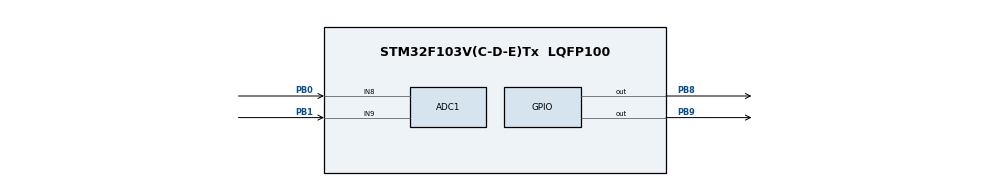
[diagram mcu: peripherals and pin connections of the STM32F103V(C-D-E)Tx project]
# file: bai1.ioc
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ADC1.Channel-1\#ChannelRegularConversion=ADC_CHANNEL_8
ADC1.Channel-2\#ChannelRegularConversion=ADC_CHANNEL_9
ADC1.ContinuousConvMode=ENABLE
ADC1.NbrOfConversion=2
ADC1.NbrOfConversionFlag=1
ADC1.Rank-1\#ChannelRegularConversion=1
ADC1.Rank-2\#ChannelRegularConversion=2
ADC1.SamplingTime-1\#ChannelRegularConversion=ADC_SAMPLETIME_1CYCLE_5
ADC1.SamplingTime-2\#ChannelRegularConversion=ADC_SAMPLETIME_1CYCLE_5
ADC1.master=1
Dma.ADC1.0.Direction=DMA_PERIPH_TO_MEMORY
Dma.ADC1.0.Instance=DMA1_Channel1
Dma.ADC1.0.MemDataAlignment=DMA_MDATAALIGN_HALFWORD
Dma.ADC1.0.MemInc=DMA_MINC_ENABLE
Dma.ADC1.0.Mode=DMA_CIRCULAR
Dma.ADC1.0.PeriphDataAlignment=DMA_PDATAALIGN_HALFWORD
Dma.ADC1.0.PeriphInc=DMA_PINC_DISABLE
Dma.ADC1.0.Priority=DMA_PRIORITY_MEDIUM
Dma.Request0=ADC1
FREERTOS.Tasks01=ADC_Task,0,128,StartDefaultTask,Default,NULL,Dynamic,NULL,NULL;Display_Task,0,128,StartTask02,Default,NULL,Dynamic,NULL,NULL
Mcu.Family=STM32F1
Mcu.Name=STM32F103V(C-D-E)Tx
Mcu.Package=LQFP100
NVIC.DMA1_Channel1_IRQn=true\:5\:0\:false\:false\:true\:true\:false\:true\:true
NVIC.PriorityGroup=NVIC_PRIORITYGROUP_4
OSC_IN.Mode=HSE-External-Oscillator
OSC_IN.Signal=RCC_OSC_IN
OSC_OUT.Mode=HSE-External-Oscillator
OSC_OUT.Signal=RCC_OSC_OUT
PA13.Mode=Serial_Wire
PA13.Signal=SYS_JTMS-SWDIO
PA14.Mode=Serial_Wire
PA14.Signal=SYS_JTCK-SWCLK
PB0.Signal=ADCx_IN8
PB1.Signal=ADCx_IN9
PB8.Signal=GPIO_Output
PB9.Signal=GPIO_Output
ProjectManager.HeapSize=0x200
ProjectManager.StackSize=0x400
ProjectManager.TargetToolchain=STM32CubeIDE
RCC.APB1Freq_Value=8000000
RCC.APB2Freq_Value=8000000
SH.ADCx_IN8.0=ADC1_IN8,IN8
SH.ADCx_IN9.0=ADC1_IN9,IN9
VP_FREERTOS_VS_CMSIS_V1.Mode=CMSIS_V1
board=custom

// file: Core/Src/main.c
/* USER CODE BEGIN Header */
/**
  ******************************************************************************
  * @file           : main.c
  * @brief          : Main program body
  ******************************************************************************
  * @attention
  *
  * Copyright (c) 2025 STMicroelectronics.
  * All rights reserved.
  *
  * This software is licensed under terms that can be found in the LICENSE file
  * in the root directory of this software component.
  * If no LICENSE file comes with this software, it is provided AS-IS.
  *
  ******************************************************************************
  */
/* USER CODE END Header */
#include "main.h"
#include "cmsis_os.h"
#include "LED7SEG.h"

ADC_HandleTypeDef hadc1;
DMA_HandleTypeDef hdma_adc1;

osThreadId ADC_TaskHandle;
osThreadId Display_TaskHandle;
/* USER CODE BEGIN PV */
uint16_t adc_buf[1];
uint16_t display_value = 0;
/* USER CODE END PV */

void SystemClock_Config(void);
static void MX_GPIO_Init(void);
static void MX_DMA_Init(void);
static void MX_ADC1_Init(void);
void StartDefaultTask(void const * argument);
void StartTask02(void const * argument);

int main(void)
{

  /* MCU Configuration--------------------------------------------------------*/

  /* Reset of all peripherals, Initializes the Flash interface and the Systick. */
  HAL_Init();

  /* Configure the system clock */
  SystemClock_Config();

  /* Initialize all configured peripherals */
  MX_GPIO_Init();
  MX_DMA_Init();
  MX_ADC1_Init();

  /* Create the thread(s) */
  /* definition and creation of ADC_Task */
  osThreadDef(ADC_Task, StartDefaultTask, osPriorityNormal, 0, 128);
  ADC_TaskHandle = osThreadCreate(osThread(ADC_Task), NULL);

  /* definition and creation of Display_Task */
  osThreadDef(Display_Task, StartTask02, osPriorityNormal, 0, 128);
  Display_TaskHandle = osThreadCreate(osThread(Display_Task), NULL);

  /* Start scheduler */
  osKernelStart();

  /* We should never get here as control is now taken by the scheduler */

  /* Infinite loop */
  while (1)
  {

  }
}

void SystemClock_Config(void)
{
  RCC_OscInitTypeDef RCC_OscInitStruct = {0};
  RCC_ClkInitTypeDef RCC_ClkInitStruct = {0};
  RCC_PeriphCLKInitTypeDef PeriphClkInit = {0};

  /** Initializes the RCC Oscillators according to the specified parameters
  * in the RCC_OscInitTypeDef structure.
  */
  RCC_OscInitStruct.OscillatorType = RCC_OSCILLATORTYPE_HSI;
  RCC_OscInitStruct.HSIState = RCC_HSI_ON;
  RCC_OscInitStruct.HSICalibrationValue = RCC_HSICALIBRATION_DEFAULT;
  RCC_OscInitStruct.PLL.PLLState = RCC_PLL_NONE;
  if (HAL_RCC_OscConfig(&RCC_OscInitStruct) != HAL_OK)
  {
    Error_Handler();
  }

  /** Initializes the CPU, AHB and APB buses clocks
  */
  RCC_ClkInitStruct.ClockType = RCC_CLOCKTYPE_HCLK|RCC_CLOCKTYPE_SYSCLK
                              |RCC_CLOCKTYPE_PCLK1|RCC_CLOCKTYPE_PCLK2;
  RCC_ClkInitStruct.SYSCLKSource = RCC_SYSCLKSOURCE_HSI;
  RCC_ClkInitStruct.AHBCLKDivider = RCC_SYSCLK_DIV1;
  RCC_ClkInitStruct.APB1CLKDivider = RCC_HCLK_DIV1;
  RCC_ClkInitStruct.APB2CLKDivider = RCC_HCLK_DIV1;

  if (HAL_RCC_ClockConfig(&RCC_ClkInitStruct, FLASH_LATENCY_0) != HAL_OK)
  {
    Error_Handler();
  }
  PeriphClkInit.PeriphClockSelection = RCC_PERIPHCLK_ADC;
  PeriphClkInit.AdcClockSelection = RCC_ADCPCLK2_DIV2;
  if (HAL_RCCEx_PeriphCLKConfig(&PeriphClkInit) != HAL_OK)
  {
    Error_Handler();
  }
}

static void MX_ADC1_Init(void)
{

  ADC_ChannelConfTypeDef sConfig = {0};

  /** Common config
  */
  hadc1.Instance = ADC1;
  hadc1.Init.ScanConvMode = ADC_SCAN_ENABLE;
  hadc1.Init.ContinuousConvMode = ENABLE;
  hadc1.Init.DiscontinuousConvMode = DISABLE;
  hadc1.Init.ExternalTrigConv = ADC_SOFTWARE_START;
  hadc1.Init.DataAlign = ADC_DATAALIGN_RIGHT;
  hadc1.Init.NbrOfConversion = 2;
  if (HAL_ADC_Init(&hadc1) != HAL_OK)
  {
    Error_Handler();
  }

  /** Configure Regular Channel
  */
  sConfig.Channel = ADC_CHANNEL_8;
  sConfig.Rank = ADC_REGULAR_RANK_1;
  sConfig.SamplingTime = ADC_SAMPLETIME_1CYCLE_5;
  if (HAL_ADC_ConfigChannel(&hadc1, &sConfig) != HAL_OK)
  {
    Error_Handler();
  }

  /** Configure Regular Channel
  */
  sConfig.Channel = ADC_CHANNEL_9;
  sConfig.Rank = ADC_REGULAR_RANK_2;
  if (HAL_ADC_ConfigChannel(&hadc1, &sConfig) != HAL_OK)
  {
    Error_Handler();
  }

}

static void MX_DMA_Init(void)
{

  /* DMA controller clock enable */
  __HAL_RCC_DMA1_CLK_ENABLE();

  /* DMA interrupt init */
  /* DMA1_Channel1_IRQn interrupt configuration */
  HAL_NVIC_SetPriority(DMA1_Channel1_IRQn, 5, 0);
  HAL_NVIC_EnableIRQ(DMA1_Channel1_IRQn);

}

static void MX_GPIO_Init(void)
{
  GPIO_InitTypeDef GPIO_InitStruct = {0};

  /* GPIO Ports Clock Enable */
  __HAL_RCC_GPIOB_CLK_ENABLE();
  __HAL_RCC_GPIOA_CLK_ENABLE();

  /*Configure GPIO pin Output Level */
  HAL_GPIO_WritePin(GPIOB, GPIO_PIN_8|GPIO_PIN_9, GPIO_PIN_RESET);

  /*Configure GPIO pins : PB8 PB9 */
  GPIO_InitStruct.Pin = GPIO_PIN_8|GPIO_PIN_9;
  GPIO_InitStruct.Mode = GPIO_MODE_OUTPUT_PP;
  GPIO_InitStruct.Pull = GPIO_NOPULL;
  GPIO_InitStruct.Speed = GPIO_SPEED_FREQ_LOW;
  HAL_GPIO_Init(GPIOB, &GPIO_InitStruct);

}

void StartDefaultTask(void const * argument)
{
  /* USER CODE BEGIN 5 */

	  HAL_ADC_Start_DMA(&hadc1, (uint32_t*)adc_buf, 2);  // <-- thêm dòng này
  /* Infinite loop */
  for(;;)
  {
	  display_value = adc_buf[0]; // giá trị 0–4095
	     osDelay(50);
  }
  /* USER CODE END 5 */
}

void StartTask02(void const * argument)
{
  /* USER CODE BEGIN StartTask02 */
  /* Infinite loop */
  for(;;)
  {
	  Display_7_SEG(display_value);  // Gọi hàm của mày
	      osDelay(5);
  }
  /* USER CODE END StartTask02 */
}

void Error_Handler(void)
{
  __disable_irq();
  while (1)
  {
  }
}
